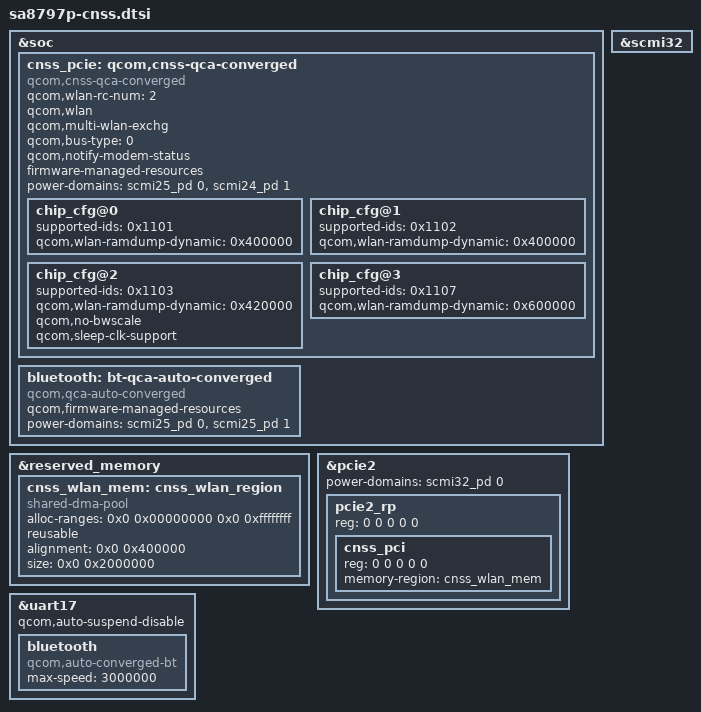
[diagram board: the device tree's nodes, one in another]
// SPDX-License-Identifier: BSD-3-Clause
/*
 * Copyright (c) Qualcomm Technologies, Inc. and/or its subsidiaries.
 */
&soc {
	cnss_pcie: qcom,cnss-qca-converged {
		compatible = "qcom,cnss-qca-converged";
		qcom,wlan-rc-num = <2>;
		qcom,wlan;
		qcom,multi-wlan-exchg;
		qcom,bus-type=<0>;
		qcom,notify-modem-status;
		firmware-managed-resources;
		#address-cells=<1>;
		#size-cells=<1>;
		ranges = <0xb0000000 0xb0000000 0x10000>;
		power-domains = <&scmi25_pd 0>, <&scmi24_pd 1>;
		power-domain-names = "wlan_ldo", "wlan_gpio";
		chip_cfg@0 {
			supported-ids = <0x1101>;
			qcom,wlan-ramdump-dynamic = <0x400000>;
		};
		chip_cfg@1 {
			supported-ids = <0x1102>;
			qcom,wlan-ramdump-dynamic = <0x400000>;
		};
		chip_cfg@2 {
			supported-ids = <0x1103>;
			qcom,wlan-ramdump-dynamic = <0x420000>;
			qcom,no-bwscale;
			qcom,sleep-clk-support;
		};
		chip_cfg@3 {
			supported-ids = <0x1107>;
			qcom,wlan-ramdump-dynamic = <0x600000>;
		};
	};
	bluetooth: bt-qca-auto-converged {
		compatible = "qcom,qca-auto-converged";
		qcom,firmware-managed-resources;
		power-domains = <&scmi25_pd 0>, <&scmi25_pd 1>;
		power-domain-names = "bt_ldo", "bt_gpio";
	};
};
&reserved_memory {
	cnss_wlan_mem: cnss_wlan_region {
		compatible = "shared-dma-pool";
		alloc-ranges = <0x0 0x00000000 0x0 0xffffffff>;
		reusable;
		alignment = <0x0 0x400000>;
		size = <0x0 0x2000000>;
	};
};
&scmi32 {
	status = "okay";
};
&pcie2 {
	status = "okay";
	power-domains = <&scmi32_pd 0>;
	power-domain-names = "power";
	pcie2_rp: pcie2_rp {
		reg = <0 0 0 0 0>;
		#address-cells = <5>;
		#size-cells = <0>;
		cnss_pci: cnss_pci {
			reg = <0 0 0 0 0>;
			memory-region = <&cnss_wlan_mem>;
		};
	};
};
&uart17 {
	status = "okay";
	qcom,auto-suspend-disable;
	bluetooth {
		compatible = "qcom,auto-converged-bt";
		max-speed = <3000000>;
	};
};

